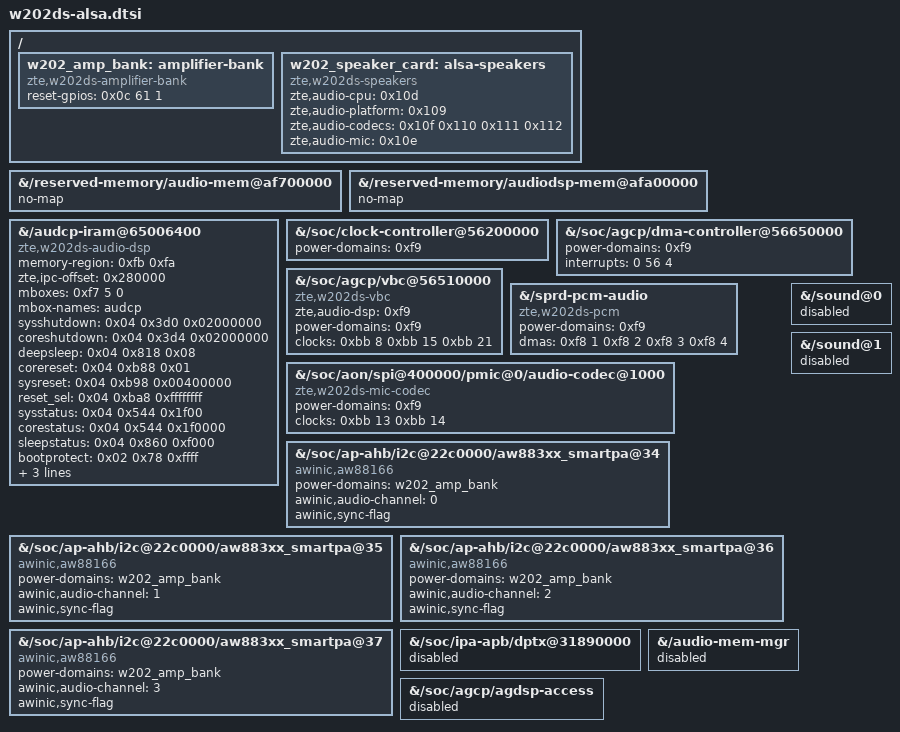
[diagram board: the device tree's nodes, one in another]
// SPDX-License-Identifier: GPL-2.0-only
// Boot-time configuration for the matching W202DS ALSA modules.
// This changes reserved-memory and ownership: never apply as a live overlay.
/ {
	w202_amp_bank: amplifier-bank {
		compatible = "zte,w202ds-amplifier-bank";
		#power-domain-cells = <0>;
		reset-gpios = <0x0c 61 1>; // shared active-low AON GPIO61
	};

	w202_speaker_card: alsa-speakers {
		compatible = "zte,w202ds-speakers";
		zte,audio-cpu = <0x10d>;
		zte,audio-platform = <0x109>;
		zte,audio-codecs = <0x10f 0x110 0x111 0x112>;
		zte,audio-mic = <0x10e>;
	};
};

&{/reserved-memory/audio-mem@af700000} { no-map; };
&{/reserved-memory/audiodsp-mem@afa00000} { no-map; };

&{/audcp-iram@65006400} {
	compatible = "zte,w202ds-audio-dsp";
	#power-domain-cells = <0>;
	memory-region = <0xfb 0xfa>; // firmware, complete existing audio reservation
	zte,ipc-offset = <0x280000>; // af700000 + 280000 = af980000
	mboxes = <0xf7 5 0>;
	mbox-names = "audcp";
	sysshutdown = <0x04 0x3d0 0x02000000>;
	coreshutdown = <0x04 0x3d4 0x02000000>;
	deepsleep = <0x04 0x818 0x08>;
	corereset = <0x04 0xb88 0x01>;
	sysreset = <0x04 0xb98 0x00400000>;
	reset_sel = <0x04 0xba8 0xffffffff>;
	sysstatus = <0x04 0x544 0x1f00>;
	corestatus = <0x04 0x544 0x1f0000>;
	sleepstatus = <0x04 0x860 0xf000>;
	bootprotect = <0x02 0x78 0xffff>;
	bootvector = <0x02 0x140 0xffffffff>;
	bootaddress_sel = <0x02 0x144 0x01>;
	ap-access = <0x02 0x14c 0x20>;
	status = "okay";
};

&{/soc/clock-controller@56200000} {
	power-domains = <0xf9>;
};

&{/soc/agcp/dma-controller@56650000} {
	power-domains = <0xf9>;
	/* W202DS AP DMA asserts GIC INTID 88 (SPI 56), not the imported SPI 55. */
	interrupts = <0 56 4>;
	status = "okay";
};

&{/soc/agcp/vbc@56510000} {
	compatible = "zte,w202ds-vbc";
	#sound-dai-cells = <0>;
	zte,audio-dsp = <0xf9>;
	power-domains = <0xf9>;
	clocks = <0xbb 8 0xbb 15 0xbb 21>;
	clock-names = "vbc", "vbc-24m", "vbc-ap";
	status = "okay";
};

&{/sprd-pcm-audio} {
	compatible = "zte,w202ds-pcm";
	power-domains = <0xf9>;
	/* AGCP DMA requests 1-4: AP01 playback L/R, AP01 record L/R (factory DT). */
	dmas = <0xf8 1 0xf8 2 0xf8 3 0xf8 4>;
	dma-names = "normal_p_l", "normal_p_r", "normal_c_l", "normal_c_r";
	status = "okay";
};

// UMP9620 analog codec; digital-codec, 26 MHz sinout and lrdat-sel stay as imported.
&{/soc/aon/spi@400000/pmic@0/audio-codec@1000} {
	compatible = "zte,w202ds-mic-codec";
	#sound-dai-cells = <0>;
	power-domains = <0xf9>;
	clocks = <0xbb 13 0xbb 14>; // CLK_AUDCP_AUD_EB, CLK_AUDIF_CKG_AUTO_EN
	clock-names = "aud", "audif";
};

&{/soc/ap-ahb/i2c@22c0000/aw883xx_smartpa@34} {
	compatible = "awinic,aw88166";
	#sound-dai-cells = <0>;
	/delete-property/ reset-gpio;
	/delete-property/ sync-load;
	/delete-property/ sound-channel;
	power-domains = <&w202_amp_bank>;
	awinic,audio-channel = <0>;
	awinic,sync-flag;
};
&{/soc/ap-ahb/i2c@22c0000/aw883xx_smartpa@35} {
	compatible = "awinic,aw88166";
	#sound-dai-cells = <0>;
	/delete-property/ sync-load;
	/delete-property/ sound-channel;
	power-domains = <&w202_amp_bank>;
	awinic,audio-channel = <1>;
	awinic,sync-flag;
};
&{/soc/ap-ahb/i2c@22c0000/aw883xx_smartpa@36} {
	compatible = "awinic,aw88166";
	#sound-dai-cells = <0>;
	/delete-property/ sync-load;
	/delete-property/ sound-channel;
	power-domains = <&w202_amp_bank>;
	awinic,audio-channel = <2>;
	awinic,sync-flag;
};
&{/soc/ap-ahb/i2c@22c0000/aw883xx_smartpa@37} {
	compatible = "awinic,aw88166";
	#sound-dai-cells = <0>;
	/delete-property/ sync-load;
	/delete-property/ sound-channel;
	power-domains = <&w202_amp_bank>;
	awinic,audio-channel = <3>;
	awinic,sync-flag;
};

// The legacy DP node also claimed GPIO61. This speaker configuration owns it.
&{/soc/ipa-apb/dptx@31890000} {
	/delete-property/ dp-gpios;
	status = "disabled";
};
&{/sound@0} { status = "disabled"; };
&{/sound@1} { status = "disabled"; };
&{/audio-mem-mgr} { status = "disabled"; };
&{/soc/agcp/agdsp-access} { status = "disabled"; };
